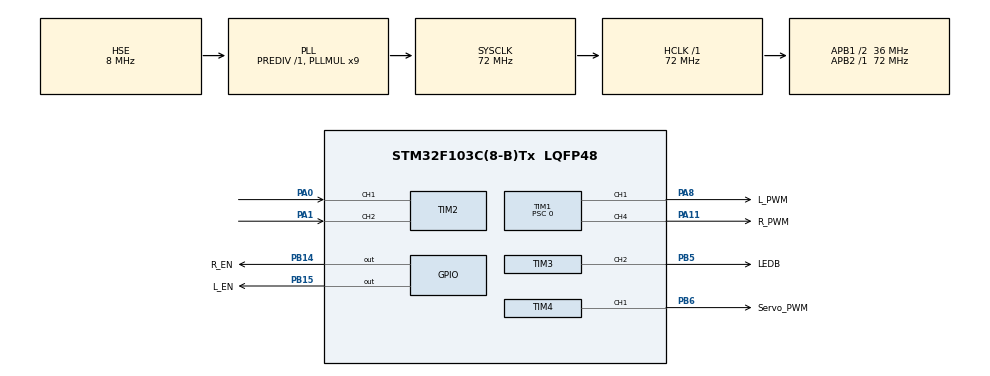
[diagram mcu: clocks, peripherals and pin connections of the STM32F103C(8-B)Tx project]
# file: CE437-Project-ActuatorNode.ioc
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Mcu.Family=STM32F1
Mcu.Name=STM32F103C(8-B)Tx
Mcu.Package=LQFP48
NVIC.PriorityGroup=NVIC_PRIORITYGROUP_4
NVIC.TIM3_IRQn=true\:0\:0\:false\:false\:true\:true\:true\:true
PA0-WKUP.Signal=S_TIM2_CH1_ETR
PA1.Signal=S_TIM2_CH2
PA11.GPIO_Label=R_PWM
PA11.Signal=S_TIM1_CH4
PA8.GPIO_Label=L_PWM
PA8.Signal=S_TIM1_CH1
PB14.GPIO_Label=R_EN
PB14.Signal=GPIO_Output
PB15.GPIO_Label=L_EN
PB15.Signal=GPIO_Output
PB5.GPIO_Label=LEDB
PB5.Signal=S_TIM3_CH2
PB6.GPIO_Label=Servo_PWM
PB6.Signal=S_TIM4_CH1
PD0-OSC_IN.Mode=HSE-External-Oscillator
PD0-OSC_IN.Signal=RCC_OSC_IN
PD1-OSC_OUT.Mode=HSE-External-Oscillator
PD1-OSC_OUT.Signal=RCC_OSC_OUT
ProjectManager.HeapSize=0x200
ProjectManager.StackSize=0x400
ProjectManager.TargetToolchain=STM32CubeIDE
RCC.AHBFreq_Value=72000000
RCC.APB1CLKDivider=RCC_HCLK_DIV2
RCC.APB1Freq_Value=36000000
RCC.APB1TimFreq_Value=72000000
RCC.APB2Freq_Value=72000000
RCC.APB2TimFreq_Value=72000000
RCC.HCLKFreq_Value=72000000
RCC.PLLMUL=RCC_PLL_MUL9
RCC.PLLSourceVirtual=RCC_PLLSOURCE_HSE
RCC.SYSCLKFreq_VALUE=72000000
RCC.SYSCLKSource=RCC_SYSCLKSOURCE_PLLCLK
RCC.USBFreq_Value=72000000
SH.S_TIM1_CH1.0=TIM1_CH1,PWM Generation1 CH1
SH.S_TIM1_CH4.0=TIM1_CH4,PWM Generation4 CH4
SH.S_TIM2_CH1_ETR.0=TIM2_CH1,Encoder_Interface
SH.S_TIM2_CH2.0=TIM2_CH2,Encoder_Interface
SH.S_TIM3_CH2.0=TIM3_CH2,PWM Generation2 CH2
SH.S_TIM4_CH1.0=TIM4_CH1,PWM Generation1 CH1
TIM1.Channel-PWM\ Generation1\ CH1=TIM_CHANNEL_1
TIM1.Channel-PWM\ Generation4\ CH4=TIM_CHANNEL_4
TIM1.Period=7199
TIM1.Prescaler=0
TIM2.EncoderMode=TIM_ENCODERMODE_TI12
TIM2.IC1Filter=5
TIM2.IC2Filter=5
TIM3.Channel-PWM\ Generation2\ CH2=TIM_CHANNEL_2
TIM3.Period=999
TIM3.Prescaler=7199
TIM4.Channel-PWM\ Generation1\ CH1=TIM_CHANNEL_1
TIM4.Period=9999
TIM4.Prescaler=719
VP_SYS_VS_ND.Mode=No_Debug
board=custom

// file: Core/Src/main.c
/* USER CODE BEGIN Header */
/**
  ******************************************************************************
  * @file           : main.c
  * @brief          : Main program body
  ******************************************************************************
  * @attention
  *
  * Copyright (c) 2024 STMicroelectronics.
  * All rights reserved.
  *
  * This software is licensed under terms that can be found in the LICENSE file
  * in the root directory of this software component.
  * If no LICENSE file comes with this software, it is provided AS-IS.
  *
  ******************************************************************************
  */
/* USER CODE END Header */
#include "main.h"
#include "tim.h"
#include "gpio.h"

/* USER CODE BEGIN Includes */
#include "motor.h"
#include "servo.h"
/* USER CODE END Includes */

/* USER CODE BEGIN PV */
MotorHandlerTypeDef 	hmotor;
ServoHandlerTypeDef	hservo;
/* USER CODE END PV */

void SystemClock_Config(void);

/* USER CODE BEGIN 0 */

void HAL_TIM_PeriodElapsedCallback(TIM_HandleTypeDef *htim)
{
  /* Prevent unused argument(s) compilation warning */
  UNUSED(htim);
}
/* USER CODE END 0 */

int main(void)
{

  /* MCU Configuration--------------------------------------------------------*/

  /* Reset of all peripherals, Initializes the Flash interface and the Systick. */
  HAL_Init();

  /* Configure the system clock */
  SystemClock_Config();

  /* Initialize all configured peripherals */
  MX_GPIO_Init();
  MX_TIM4_Init();
  MX_TIM3_Init();
  MX_TIM1_Init();
  MX_TIM2_Init();
  /* USER CODE BEGIN 2 */
  servoInit(&hservo, &htim4, TIM_CHANNEL_1, 90, 0.025, 0.005);
  servoStart(&hservo);
//  motorInit(&hmotor, &htim1, TIM_CHANNEL_4, TIM_CHANNEL_1, MAX_DUTY_CYCLE, CLOCKWISE);
//  motorStart(&hmotor);
  /* USER CODE END 2 */

  /* Infinite loop */
  while (1)
  {

    /* USER CODE BEGIN 3 */
//	setMotorPWM(&hmotor, 60);
	setServoAngle(&hservo, -20);
	HAL_Delay(2000);
	setServoAngle(&hservo, 0);
	HAL_Delay(2000);
	setServoAngle(&hservo, 20);
	HAL_Delay(2000);
  }
  /* USER CODE END 3 */
}

void SystemClock_Config(void)
{
  RCC_OscInitTypeDef RCC_OscInitStruct = {0};
  RCC_ClkInitTypeDef RCC_ClkInitStruct = {0};

  /** Initializes the RCC Oscillators according to the specified parameters
  * in the RCC_OscInitTypeDef structure.
  */
  RCC_OscInitStruct.OscillatorType = RCC_OSCILLATORTYPE_HSE;
  RCC_OscInitStruct.HSEState = RCC_HSE_ON;
  RCC_OscInitStruct.HSEPredivValue = RCC_HSE_PREDIV_DIV1;
  RCC_OscInitStruct.HSIState = RCC_HSI_ON;
  RCC_OscInitStruct.PLL.PLLState = RCC_PLL_ON;
  RCC_OscInitStruct.PLL.PLLSource = RCC_PLLSOURCE_HSE;
  RCC_OscInitStruct.PLL.PLLMUL = RCC_PLL_MUL9;
  if (HAL_RCC_OscConfig(&RCC_OscInitStruct) != HAL_OK)
  {
    Error_Handler();
  }

  /** Initializes the CPU, AHB and APB buses clocks
  */
  RCC_ClkInitStruct.ClockType = RCC_CLOCKTYPE_HCLK|RCC_CLOCKTYPE_SYSCLK
                              |RCC_CLOCKTYPE_PCLK1|RCC_CLOCKTYPE_PCLK2;
  RCC_ClkInitStruct.SYSCLKSource = RCC_SYSCLKSOURCE_PLLCLK;
  RCC_ClkInitStruct.AHBCLKDivider = RCC_SYSCLK_DIV1;
  RCC_ClkInitStruct.APB1CLKDivider = RCC_HCLK_DIV2;
  RCC_ClkInitStruct.APB2CLKDivider = RCC_HCLK_DIV1;

  if (HAL_RCC_ClockConfig(&RCC_ClkInitStruct, FLASH_LATENCY_2) != HAL_OK)
  {
    Error_Handler();
  }
}

void Error_Handler(void)
{
  __disable_irq();
  while (1)
  {
  }
}
